# MSP430F5529 register map
Vendor: msp430gen; File version: VERGEN_IDEMPOTENT_OUTPUT
Registers are 8-bit, read-write, reset 0x0 unless marked. A register's access mark holds for its fields unless they carry their own. Offsets are from the block's base; [hi:lo] are bit positions; {n}, {i} and the like mark numbered series.

## SHARED_REFERENCE
Base 0x000001B0
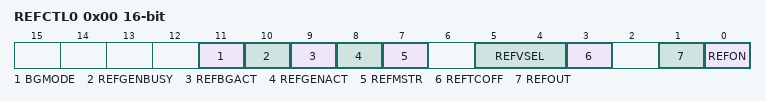
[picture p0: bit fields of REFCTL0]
0x00 REFCTL0 16-bit — REF Shared Reference control register 0
  [11] BGMODE — REF Bandgap mode
  [10] REFGENBUSY — REF Reference generator busy
  [9] REFBGACT — REF Reference bandgap active
  [8] REFGENACT — REF Reference generator active
  [7] REFMSTR — REF Master Control
  [5:4] REFVSEL — REF Reference Voltage Level Select Bit:0
    0=REF Reference Voltage Level Select 1.5V; 1=REF Reference Voltage Level Select 2.0V; 2=REF Reference Voltage Level Select 2.5V; 3=REF Reference Voltage Level Select 2.5V
  [3] REFTCOFF — REF Temp.Sensor off
  [1] REFOUT — REF Reference output Buffer On
  [0] REFON — REF Reference On

## PORT_MAPPING_CONTROL
Base 0x000001C0
0x00 PMAPKEYID 16-bit — Port Mapping Key register
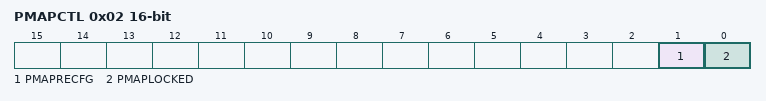
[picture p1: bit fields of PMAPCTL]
0x02 PMAPCTL 16-bit — Port Mapping control register
  [1] PMAPRECFG — Port Mapping re-configuration control bit
  [0] PMAPLOCKED — Port Mapping Lock bit. Read only

## PORT_J
Base 0x00000320
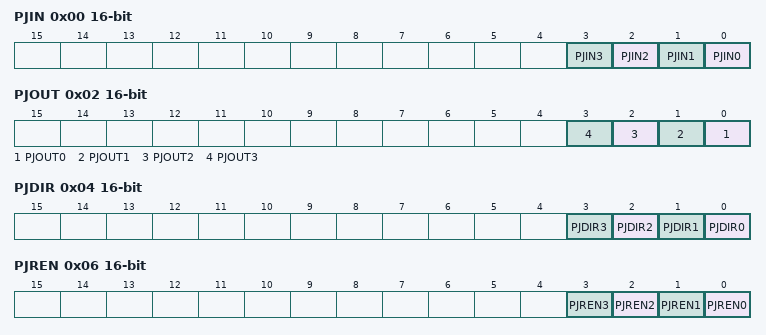
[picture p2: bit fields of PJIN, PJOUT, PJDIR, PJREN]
0x00 PJIN 16-bit — Port J Input
  [n] PJIN{n} (n=0..3)
0x02 PJOUT 16-bit — Port J Output
  [n] PJOUT{n} (n=0..3)
0x04 PJDIR 16-bit — Port J Direction
  [n] PJDIR{n} (n=0..3)
0x06 PJREN 16-bit — Port J Resistor Enable
  [n] PJREN{n} (n=0..3)
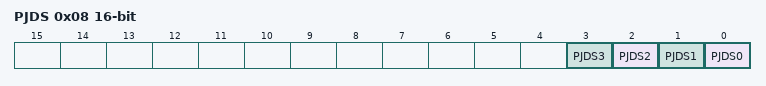
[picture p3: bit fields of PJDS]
0x08 PJDS 16-bit — Port J Drive Strenght
  [n] PJDS{n} (n=0..3)

## TIMER_0_A5
Base 0x00000340
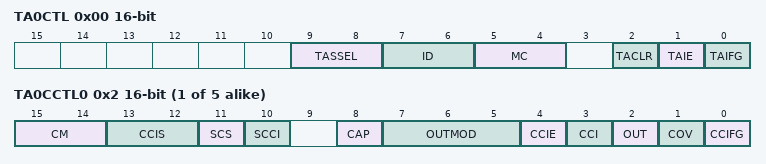
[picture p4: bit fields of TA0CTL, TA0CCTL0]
0x00 TA0CTL 16-bit — Timer0_A5 Control
  [9:8] TASSEL — Timer A clock source select 1
    0=Timer A clock source select: 0 - TACLK; 1=Timer A clock source select: 1 - ACLK; 2=Timer A clock source select: 2 - SMCLK; 3=Timer A clock source select: 3 - INCLK
  [7:6] ID — Timer A clock input divider 1
    0=Timer A input divider: 0 - /1; 1=Timer A input divider: 1 - /2; 2=Timer A input divider: 2 - /4; 3=Timer A input divider: 3 - /8
  [5:4] MC — Timer A mode control 1
    0=Timer A mode control: 0 - Stop; 1=Timer A mode control: 1 - Up to CCR0; 2=Timer A mode control: 2 - Continuous up; 3=Timer A mode control: 3 - Up/Down
  [2] TACLR — Timer A counter clear
  [1] TAIE — Timer A counter interrupt enable
  [0] TAIFG — Timer A counter interrupt flag
{0x2+2i} TA0CCTL{i} 16-bit (i=0..4) — Timer0_A5 Capture/Compare Control {i}
  [15:14] CM — Capture mode 1
    0=Capture mode: 0 - disabled; 1=Capture mode: 1 - pos. edge; 2=Capture mode: 1 - neg. edge; 3=Capture mode: 1 - both edges
  [13:12] CCIS — Capture input select 1
    0=Capture input select: 0 - CCIxA; 1=Capture input select: 1 - CCIxB; 2=Capture input select: 2 - GND; 3=Capture input select: 3 - Vcc
  [11] SCS — Capture sychronize
  [10] SCCI — Latched capture signal (read)
  [8] CAP — Capture mode: 1 /Compare mode : 0
  [7:5] OUTMOD — Output mode 2
    0=PWM output mode: 0 - output only; 1=PWM output mode: 1 - set; 2=PWM output mode: 2 - PWM toggle/reset; 3=PWM output mode: 3 - PWM set/reset; 4=PWM output mode: 4 - toggle; 5=PWM output mode: 5 - Reset; 6=PWM output mode: 6 - PWM toggle/set; 7=PWM output mode: 7 - PWM reset/set
  [4] CCIE — Capture/compare interrupt enable
  [3] CCI — Capture input signal (read)
  [2] OUT — PWM Output signal if output mode 0
  [1] COV — Capture/compare overflow flag
  [0] CCIFG — Capture/compare interrupt flag
0x10 TA0R 16-bit — Timer0_A5
{0x12+2i} TA0CCR{i} 16-bit (i=0..4) — Timer0_A5 Capture/Compare {i}
0x20 TA0EX0 16-bit — Timer0_A5 Expansion Register 0
  [2:0] TAIDEX — Timer A Input divider expansion Bit: 0
    {v}=Timer A Input divider expansion : /{v+1} (v=0..7)
0x2E TA0IV 16-bit — Timer0_A5 Interrupt Vector Word

## TIMER_1_A3
Base 0x00000380
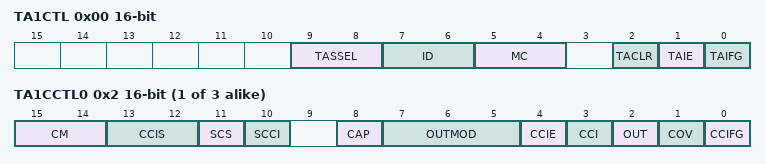
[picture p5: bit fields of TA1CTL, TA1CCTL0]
0x00 TA1CTL 16-bit — Timer1_A3 Control
  [9:8] TASSEL — Timer A clock source select 1
    0=Timer A clock source select: 0 - TACLK; 1=Timer A clock source select: 1 - ACLK; 2=Timer A clock source select: 2 - SMCLK; 3=Timer A clock source select: 3 - INCLK
  [7:6] ID — Timer A clock input divider 1
    0=Timer A input divider: 0 - /1; 1=Timer A input divider: 1 - /2; 2=Timer A input divider: 2 - /4; 3=Timer A input divider: 3 - /8
  [5:4] MC — Timer A mode control 1
    0=Timer A mode control: 0 - Stop; 1=Timer A mode control: 1 - Up to CCR0; 2=Timer A mode control: 2 - Continuous up; 3=Timer A mode control: 3 - Up/Down
  [2] TACLR — Timer A counter clear
  [1] TAIE — Timer A counter interrupt enable
  [0] TAIFG — Timer A counter interrupt flag
{0x2+2i} TA1CCTL{i} 16-bit (i=0..2) — Timer1_A3 Capture/Compare Control {i}
  [15:14] CM — Capture mode 1
    0=Capture mode: 0 - disabled; 1=Capture mode: 1 - pos. edge; 2=Capture mode: 1 - neg. edge; 3=Capture mode: 1 - both edges
  [13:12] CCIS — Capture input select 1
    0=Capture input select: 0 - CCIxA; 1=Capture input select: 1 - CCIxB; 2=Capture input select: 2 - GND; 3=Capture input select: 3 - Vcc
  [11] SCS — Capture sychronize
  [10] SCCI — Latched capture signal (read)
  [8] CAP — Capture mode: 1 /Compare mode : 0
  [7:5] OUTMOD — Output mode 2
    0=PWM output mode: 0 - output only; 1=PWM output mode: 1 - set; 2=PWM output mode: 2 - PWM toggle/reset; 3=PWM output mode: 3 - PWM set/reset; 4=PWM output mode: 4 - toggle; 5=PWM output mode: 5 - Reset; 6=PWM output mode: 6 - PWM toggle/set; 7=PWM output mode: 7 - PWM reset/set
  [4] CCIE — Capture/compare interrupt enable
  [3] CCI — Capture input signal (read)
  [2] OUT — PWM Output signal if output mode 0
  [1] COV — Capture/compare overflow flag
  [0] CCIFG — Capture/compare interrupt flag
0x10 TA1R 16-bit — Timer1_A3
{0x12+2i} TA1CCR{i} 16-bit (i=0..2) — Timer1_A3 Capture/Compare {i}
0x20 TA1EX0 16-bit — Timer1_A3 Expansion Register 0
  [2:0] TAIDEX — Timer A Input divider expansion Bit: 0
    {v}=Timer A Input divider expansion : /{v+1} (v=0..7)
0x2E TA1IV 16-bit — Timer1_A3 Interrupt Vector Word
